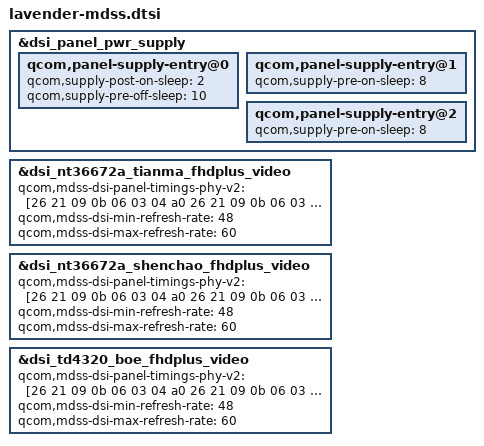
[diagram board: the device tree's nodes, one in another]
/* sdm660-mdss-panels.dtsi diff */
#include "display/dsi-panel-tianma-nt36672a-1080p-video.dtsi"
#include "display/dsi-panel-shenchao-nt36672a-1080p-video.dtsi"
#include "display/dsi-panel-boe-td4320-1080p-video.dtsi"

&dsi_panel_pwr_supply {
	qcom,panel-supply-entry@0 {
		qcom,supply-post-on-sleep = <2>;
		qcom,supply-pre-off-sleep = <10>;
	};

	qcom,panel-supply-entry@1 {
		qcom,supply-pre-on-sleep = <8>;
	};

	qcom,panel-supply-entry@2 {
		qcom,supply-pre-on-sleep = <8>;
	};
};

&dsi_nt36672a_tianma_fhdplus_video {
        qcom,mdss-dsi-panel-timings-phy-v2 = [26 21 09 0b 06 03 04 a0
               26 21 09 0b 06 03 04 a0
               26 21 09 0b 06 03 04 a0
               26 21 09 0b 06 03 04 a0
               26 20 0a 0b 06 03 04 a0];
	qcom,mdss-dsi-min-refresh-rate = <48>;
        qcom,mdss-dsi-max-refresh-rate = <60>;
};

&dsi_nt36672a_shenchao_fhdplus_video {
        qcom,mdss-dsi-panel-timings-phy-v2 = [26 21 09 0b 06 03 04 a0
               26 21 09 0b 06 03 04 a0
               26 21 09 0b 06 03 04 a0
               26 21 09 0b 06 03 04 a0
               26 20 0a 0b 06 03 04 a0];
	qcom,mdss-dsi-min-refresh-rate = <48>;
        qcom,mdss-dsi-max-refresh-rate = <60>;
};

&dsi_td4320_boe_fhdplus_video {
        qcom,mdss-dsi-panel-timings-phy-v2 = [26 21 09 0b 06 03 04 a0
               26 21 09 0b 06 03 04 a0
               26 21 09 0b 06 03 04 a0
               26 21 09 0b 06 03 04 a0
               26 20 0a 0b 06 03 04 a0];
	qcom,mdss-dsi-min-refresh-rate = <48>;
        qcom,mdss-dsi-max-refresh-rate = <60>;
};

